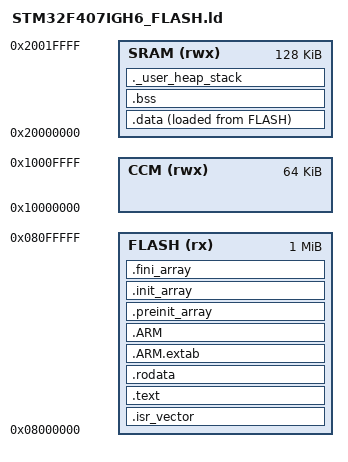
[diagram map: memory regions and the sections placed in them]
/*
 * Linker script for STM32F407IGH6 (GCC)
 * 1MB Flash
 * SRAM1+SRAM2: 128KB @ 0x20000000  (contiguous)
 * CCM:          64KB @ 0x10000000  (core-coupled, no DMA access)
 */

ENTRY(Reset_Handler)

/* Stack pointer 初始值 = SRAM 顶部 */
_estack = ORIGIN(SRAM) + LENGTH(SRAM);

/* Heap / Stack 大小 */
_Min_Heap_Size  = 0x8000;  /* 32KB */
_Min_Stack_Size = 0x8000;  /* 32KB */

MEMORY
{
    FLASH (rx)  : ORIGIN = 0x08000000, LENGTH = 1024K
    SRAM  (rwx) : ORIGIN = 0x20000000, LENGTH = 128K
    CCM   (rwx) : ORIGIN = 0x10000000, LENGTH = 64K
}

SECTIONS
{
    /* ISR vector table — must be at 0x08000000 */
    .isr_vector :
    {
        . = ALIGN(4);
        KEEP(*(.isr_vector))
        . = ALIGN(4);
    } >FLASH

    /* Code */
    .text :
    {
        . = ALIGN(4);
        *(.text)
        *(.text*)
        *(.glue_7)
        *(.glue_7t)
        *(.eh_frame)

        KEEP(*(.init))
        KEEP(*(.fini))
        . = ALIGN(4);
        _etext = .;
    } >FLASH

    /* Read-only data */
    .rodata :
    {
        . = ALIGN(4);
        *(.rodata)
        *(.rodata*)
        . = ALIGN(4);
    } >FLASH

    /* ARM exception unwind tables */
    .ARM.extab :
    {
        *(.ARM.extab* .gnu.linkonce.armextab.*)
    } >FLASH

    .ARM :
    {
        __exidx_start = .;
        *(.ARM.exidx*)
        __exidx_end = .;
    } >FLASH

    /* C++ constructors / destructors */
    .preinit_array :
    {
        PROVIDE_HIDDEN(__preinit_array_start = .);
        KEEP(*(.preinit_array*))
        PROVIDE_HIDDEN(__preinit_array_end = .);
    } >FLASH

    .init_array :
    {
        PROVIDE_HIDDEN(__init_array_start = .);
        KEEP(*(SORT(.init_array.*)))
        KEEP(*(.init_array*))
        PROVIDE_HIDDEN(__init_array_end = .);
    } >FLASH

    .fini_array :
    {
        PROVIDE_HIDDEN(__fini_array_start = .);
        KEEP(*(SORT(.fini_array.*)))
        KEEP(*(.fini_array*))
        PROVIDE_HIDDEN(__fini_array_end = .);
    } >FLASH

    /* Data — loaded from FLASH, copied to SRAM by startup code */
    _sidata = LOADADDR(.data);

    .data :
    {
        . = ALIGN(4);
        _sdata = .;
        *(.data)
        *(.data*)
        . = ALIGN(4);
        _edata = .;
    } >SRAM AT> FLASH

    /* BSS — zero-initialized */
    .bss :
    {
        . = ALIGN(4);
        _sbss = .;
        __bss_start__ = _sbss;
        *(.bss)
        *(.bss*)
        *(COMMON)
        . = ALIGN(4);
        _ebss = .;
        __bss_end__ = _ebss;
    } >SRAM

    /* Heap — grows upward, stack grows downward from _estack */
    ._user_heap_stack :
    {
        . = ALIGN(8);
        PROVIDE(end = .);
        PROVIDE(_end = .);
        . = . + _Min_Heap_Size;
        . = . + _Min_Stack_Size;
        . = ALIGN(8);
    } >SRAM

    /DISCARD/ :
    {
        libc.a(*)
        libm.a(*)
        libgcc.a(*)
    }
}
